VERSION "1.0"

NS_ :

BS_:

BU_: BMS VCU ADAS INSTRUMENT

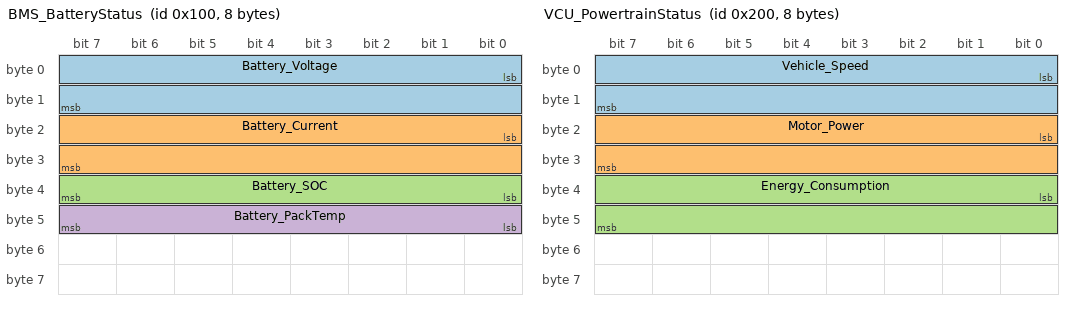
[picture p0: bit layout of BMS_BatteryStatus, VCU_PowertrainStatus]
BO_ 256 BMS_BatteryStatus: 8 BMS
 SG_ Battery_Voltage : 0|16@1+ (0.1,0) [0|1000] "V" INSTRUMENT,VCU
 SG_ Battery_Current : 16|16@1- (0.1,0) [-1000|1000] "A" INSTRUMENT,VCU
 SG_ Battery_SOC : 32|8@1+ (0.5,0) [0|100] "%" INSTRUMENT,VCU
 SG_ Battery_PackTemp : 40|8@1- (1,-40) [-40|120] "C" INSTRUMENT,VCU

BO_ 512 VCU_PowertrainStatus: 8 VCU
 SG_ Vehicle_Speed : 0|16@1+ (0.01,0) [0|300] "km/h" INSTRUMENT,ADAS
 SG_ Motor_Power : 16|16@1- (0.1,0) [-200|500] "kW" INSTRUMENT
 SG_ Energy_Consumption : 32|16@1+ (0.1,0) [0|100] "kWh/100km" INSTRUMENT

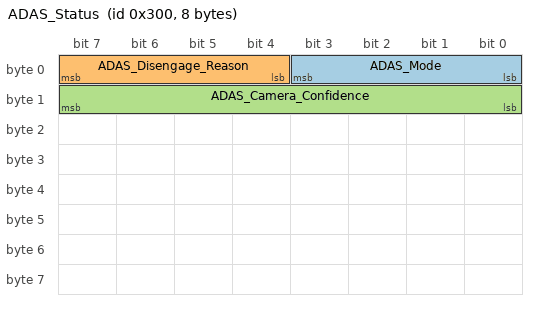
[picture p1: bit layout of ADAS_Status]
BO_ 768 ADAS_Status: 8 ADAS
 SG_ ADAS_Mode : 0|4@1+ (1,0) [0|15] "" INSTRUMENT
 SG_ ADAS_Disengage_Reason : 4|4@1+ (1,0) [0|15] "" INSTRUMENT
 SG_ ADAS_Camera_Confidence : 8|8@1+ (1,0) [0|100] "%" INSTRUMENT
